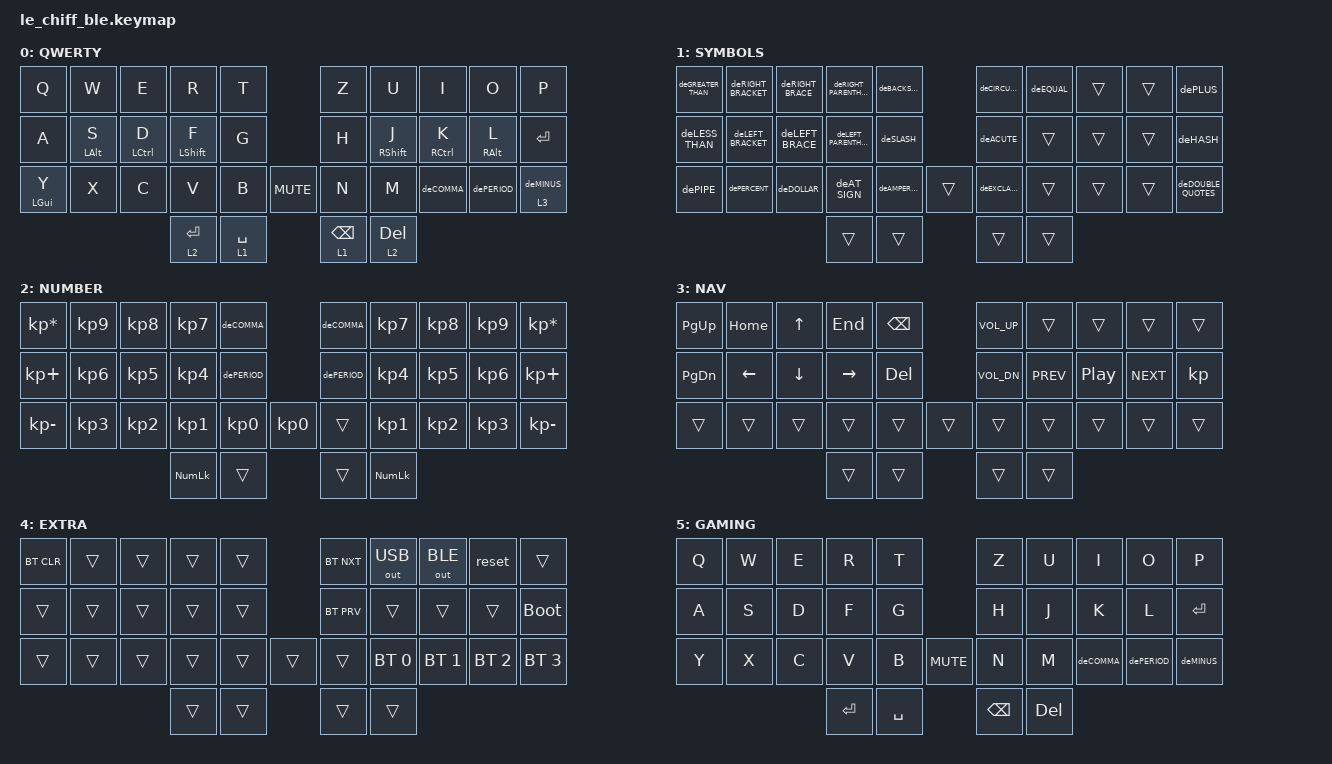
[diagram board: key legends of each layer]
/*
 * Copyright (c) 2021 @MangoIV
 *
 * SPDX-License-Identifier: MIT
 */

#include <behaviors.dtsi>
#include "language_german.dtsi"
#include <dt-bindings/zmk/keys.h>
#include <dt-bindings/zmk/bt.h>
#include <dt-bindings/zmk/outputs.h>

// makes it possible to hold backspace
&mt {
    quick_tap_ms = <200>;
};

&lt {
    quick_tap_ms = <200>;
};

/ {
	behaviors {
		hm: homerow_mods {
			compatible = "zmk,behavior-hold-tap";
			label = "homerow mods";
			#binding-cells = <2>;
			tapping_term_ms = <200>;
			flavor = "tap-preferred";
			bindings = <&kp>, <&kp>;
		};
	};


	combos {
        compatible = "zmk,combos";
        combo_nav {
            timeout-ms = <40>;
            key-positions = <31 32>;
            bindings = <&tog 3>;
        };
        combo_extra {
            timeout-ms = <40>;
            key-positions = <8 9>;
            bindings = <&tog 4>;
        };
        combo_gaming {
            timeout-ms = <40>;
            key-positions = <15 16 17>;
            bindings = <&tog 5>;
        };

        combo_ue {
            timeout-ms = <40>;
            key-positions = <6 2>;
            bindings = <&kp deUE>;
        };
    	combo_oe {
            timeout-ms = <40>;
            key-positions = <8 2>;
            bindings = <&kp deOE>;
        };
	    combo_ae {
            timeout-ms = <40>;
            key-positions = <10 2>;
            bindings = <&kp deAE>;
        };
        combo_ss {
            timeout-ms = <40>;
            key-positions = <11 12>;
            bindings = <&kp deESZETT>;
        }; 

        combo_esc {
            timeout-ms = <40>;
            key-positions = <13 14>;
            bindings = <&kp ESCAPE>;
        };
        combo_tab {
            timeout-ms = <40>;
            key-positions = <23 24>;
            bindings = <&kp TAB>;
        };

        combo_F1 {
            timeout-ms = <40>;
            key-positions = <0 10>;
            bindings = <&kp F1>;
        };
        combo_F2 {
            timeout-ms = <40>;
            key-positions = <1 11>;
            bindings = <&kp F2>;
        };
        combo_F3 {
            timeout-ms = <40>;
            key-positions = <2 12>;
            bindings = <&kp F3>;
        };
        combo_F4 {
            timeout-ms = <40>;
            key-positions = <3 13>;
            bindings = <&kp F4>;
        };
        combo_F5 {
            timeout-ms = <40>;
            key-positions = <4 14>;
            bindings = <&kp F5>;
        };
        combo_F6 {
            timeout-ms = <40>;
            key-positions = <5 15>;
            bindings = <&kp F6>;
        };
        combo_F7 {
            timeout-ms = <40>;
            key-positions = <6 16>;
            bindings = <&kp F7>;
        };
        combo_F8 {
            timeout-ms = <40>;
            key-positions = <7 17>;
            bindings = <&kp F8>;
        };
        combo_F9 {
            timeout-ms = <40>;
            key-positions = <8 18>;
            bindings = <&kp F1>;
        };
        combo_F10 {
            timeout-ms = <40>;
            key-positions = <9 19>;
            bindings = <&kp F10>;
        };
        combo_F11 {
            timeout-ms = <40>;
            key-positions = <0 1>;
            bindings = <&kp F11>;
        };
        combo_F12 {
            timeout-ms = <40>;
            key-positions = <8 9>;
            bindings = <&kp F12>;
        };
    };
};

/ {
	keymap {
		compatible = "zmk,keymap";
		
		default {
            label = "QWERTY";

			bindings = <
			//  0           1          2           3           4    /*       */       5          6           7           8            9  
            &kp Q       &kp W      &kp E       &kp R       &kp T    /*       */   &kp Z      &kp U       &kp I       &kp O        &kp P
			//  10          11         12          13          14   /*       */       15         16          17          18           19
            &kp A       &hm LALT S &hm LCTRL D &hm LSHFT F &kp G    /*       */   &kp H      &hm RSHFT J &hm RCTRL K &hm RALT L   &kp RET
			//	20          21         22          23          24   /*   25  */       26         27          28          29           30	
            &hm LGUI Y  &kp X      &kp C       &kp V       &kp B     &kp C_MUTE   &kp N      &kp M       &kp deCOMMA &kp dePERIOD &lt 3 deMINUS

      //                                   31        32                              33         34
                                           &lt 2 RET &lt 1 SPACE             		 &lt 1 BSPC &lt 2 DEL
			>;
			sensor-bindings = <&inc_dec_kp C_VOL_DN C_VOL_UP>;
		};
		symbols {
            label = "SYMBOLS";

			bindings = <
            &kp deGREATER_THAN &kp deRIGHT_BRACKET &kp deRIGHT_BRACE &kp  deRIGHT_PARENTHESIS &kp deBACKSLASH /**/   &kp deCIRCUMFLEX  &kp deEQUAL &trans &trans &kp dePLUS 
            &kp deLESS_THAN    &kp deLEFT_BRACKET  &kp deLEFT_BRACE  &kp  deLEFT_PARENTHESIS  &kp deSLASH     /**/   &kp deACUTE       &trans      &trans &trans &kp deHASH 
            &kp dePIPE         &kp dePERCENT       &kp deDOLLAR      &kp  deAT_SIGN           &kp deAMPERSAND &trans &kp deEXCLAMATION &trans      &trans &trans &kp deDOUBLE_QUOTES     
                                                                     &trans                   &trans          /**/   &trans            &trans
			>;
			sensor-bindings = <&inc_dec_kp PG_UP PG_DN>;
		};
        number {
            label = "NUMBER";
            bindings = <
            &kp KP_ASTERISK &kp KP_N9 &kp KP_N8 &kp KP_N7   &kp deCOMMA  &kp deCOMMA  /**/  &kp KP_N7   &kp KP_N8 &kp KP_N9 &kp KP_ASTERISK 
            &kp KP_PLUS     &kp KP_N6 &kp KP_N5 &kp KP_N4   &kp dePERIOD &kp dePERIOD /**/  &kp KP_N4   &kp KP_N5 &kp KP_N6 &kp KP_PLUS     
            &kp KP_MINUS    &kp KP_N3 &kp KP_N2 &kp KP_N1   &kp KP_N0    &kp KP_N0   &trans &kp KP_N1   &kp KP_N2 &kp KP_N3 &kp KP_MINUS    
                                                            &kp KP_NLCK  &trans       /**/  &trans      &kp KP_NLCK
            >;
        };

        nav {
            label = "NAV";
            bindings = <
            &kp PG_UP &kp HOME &kp UP   &kp END   &kp BSPC  /**/  &kp C_VOL_UP &trans     &trans           &trans     &trans 
            &kp PG_DN &kp LEFT &kp DOWN &kp RIGHT &kp DEL   /**/  &kp C_VOL_DN &kp C_PREV &kp C_PLAY_PAUSE &kp C_NEXT &kp    
            &trans    &trans   &trans   &trans    &trans   &trans &trans       &trans     &trans           &trans     &trans 
                                        &trans    &trans    /**/  &trans       &trans         
            >;
        };

        extra {
            label = "EXTRA";
            bindings = <
            &bt BT_CLR &trans &trans &trans &trans             &bt BT_NXT &out OUT_USB &out OUT_BLE  &reset   &trans       
            &trans     &trans &trans &trans &trans             &bt BT_PRV &trans       &trans        &trans   &bootloader  
            &trans     &trans &trans &trans &trans    &trans   &trans &bt BT_SEL 0 &bt BT_SEL 1  &bt BT_SEL 2 &bt BT_SEL 3 
                                        &trans &trans             &trans     &trans       
            >;
        };

        gaming {
            label = "GAMING";

            bindings = <
            &kp Q  &kp W &kp E &kp R   &kp T      /*       */   &kp Z    &kp U &kp I       &kp O        &kp P
            &kp A  &kp S &kp D &kp F   &kp G      /*       */   &kp H    &kp J &kp K       &kp L        &kp RET
            &kp Y  &kp X &kp C &kp V   &kp B       &kp C_MUTE   &kp N    &kp M &kp deCOMMA &kp dePERIOD &kp deMINUS

                               &kp RET &kp SPACE             	&kp BSPC &kp DEL
            >;
        };
	};
};
